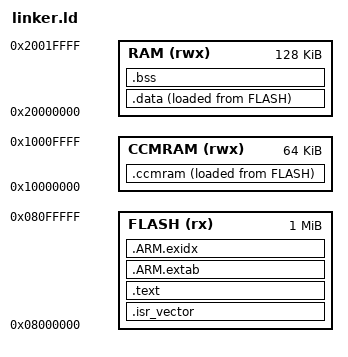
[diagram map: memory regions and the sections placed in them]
MEMORY
{
    FLASH (rx)  : ORIGIN = 0x08000000, LENGTH = 1024K
    RAM (rwx)   : ORIGIN = 0x20000000, LENGTH = 128K
    CCMRAM (rwx): ORIGIN = 0x10000000, LENGTH = 64K
}

_estack = ORIGIN(RAM) + LENGTH(RAM);

ENTRY(Reset_Handler)

SECTIONS
{
    .isr_vector :
    {
        . = ALIGN(4);
        KEEP(*(.isr_vector))
        . = ALIGN(4);
    } >FLASH

    .text :
    {
        . = ALIGN(4);
        *(.text)
        *(.text*)
        *(.glue_*)
        *(.rodata)
        *(.rodata*)
        . = ALIGN(4);
    } >FLASH

    .ARM.extab :
    {
        *(.ARM.extab* .gnu.linkonce.armextab.*)
    } >FLASH

    .ARM.exidx :
    {
        *(.ARM.exidx* .gnu.linkonce.armexidx.*)
    } >FLASH

    _sidata = LOADADDR(.data);
    .data :
    {
        . = ALIGN(4);
        _sdata = .;
        *(.data)
        *(.data*)
        . = ALIGN(4);
        _edata = .;
    } >RAM AT> FLASH

    .bss :
    {
        . = ALIGN(4);
        _sbss = .;
        __bss_start__ = _sbss;
        *(.bss)
        *(.bss*)
        *(COMMON)
        . = ALIGN(4);
        _ebss = .;
        __bss_end__ = _ebss;
    } >RAM

    .ccmram :
    {
        . = ALIGN(4);
        _sccmram = .;
        *(.ccmram)
        *(.ccmram*)
        . = ALIGN(4);
        _eccmram = .;
    } >CCMRAM AT> FLASH
}
